# STM32H7B3x register map
File version: 2.2
CPU: CM7 r0p1, little endian, MPU, FPU, 4 interrupt priority bits
Registers are 32-bit, read-write, reset 0x0 unless marked. A register's access mark holds for its fields unless they carry their own. Offsets are from the block's base; [hi:lo] are bit positions; {n}, {i} and the like mark numbered series; 'fields as' and 'values as' point back to an identical list.

## TIM12 — General purpose timers
Base 0x40001800
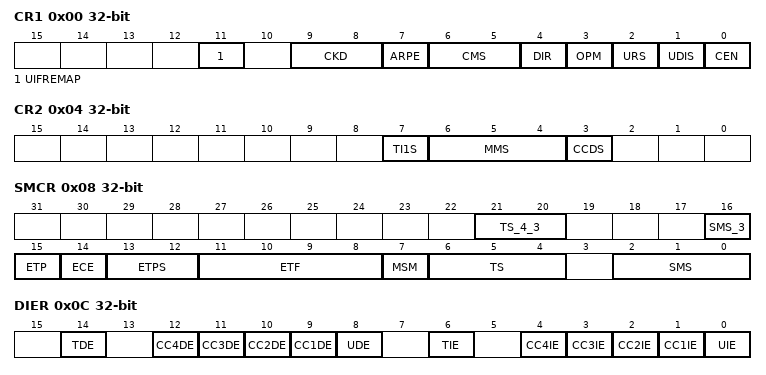
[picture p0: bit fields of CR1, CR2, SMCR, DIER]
0x00 CR1 — control register 1
  [11] UIFREMAP — UIF status bit remapping
  [9:8] CKD — Clock division
    0=Div1 (t_DTS = t_CK_INT); 1=Div2 (t_DTS = 2 × t_CK_INT); 2=Div4 (t_DTS = 4 × t_CK_INT)
  [7] ARPE — Auto-reload preload enable
    0=Disabled (TIMx_APRR register is not buffered); 1=Enabled (TIMx_APRR register is buffered)
  [6:5] CMS — Center-aligned mode selection
  [4] DIR — Direction
  [3] OPM — One-pulse mode
    0=Disabled (Counter is not stopped at update event); 1=Enabled (Counter stops counting at the next update event (clearing the CEN bit))
  [2] URS — Update request source
    0=AnyEvent (Any of counter overflow/underflow, setting UG, or update through slave mode, generates an update interrupt or DMA request); 1=CounterOnly (Only counter overflow/underflow generates an update interrupt or DMA request)
  [1] UDIS — Update disable
    0=Enabled (Update event enabled); 1=Disabled (Update event disabled)
  [0] CEN — Counter enable
    0=Disabled (Counter disabled); 1=Enabled (Counter enabled)
0x04 CR2 — control register 2
  [7] TI1S — TI1 selection
  [6:4] MMS — Master mode selection
  [3] CCDS — Capture/compare DMA selection
0x08 SMCR — slave mode control register
  [21:20] TS_4_3 — Trigger selection
  [16] SMS_3 — Slave mode selection - bit 3
  [15] ETP — External trigger polarity
  [14] ECE — External clock enable
  [13:12] ETPS — External trigger prescaler
  [11:8] ETF — External trigger filter
  [7] MSM — Master/Slave mode
  [6:4] TS — Trigger selection
  [2:0] SMS — Slave mode selection
0x0C DIER — DMA/Interrupt enable register
  [14] TDE — Trigger DMA request enable
  [n+8] CC{n}DE (n=1..4) — Capture/Compare {n} DMA request enable
  [8] UDE — Update DMA request enable
  [6] TIE — Trigger interrupt enable
  [n] CC{n}IE (n=1..4) — Capture/Compare {n} interrupt enable
  [0] UIE — Update interrupt enable
    0=Disabled (Update interrupt disabled); 1=Enabled (Update interrupt enabled)
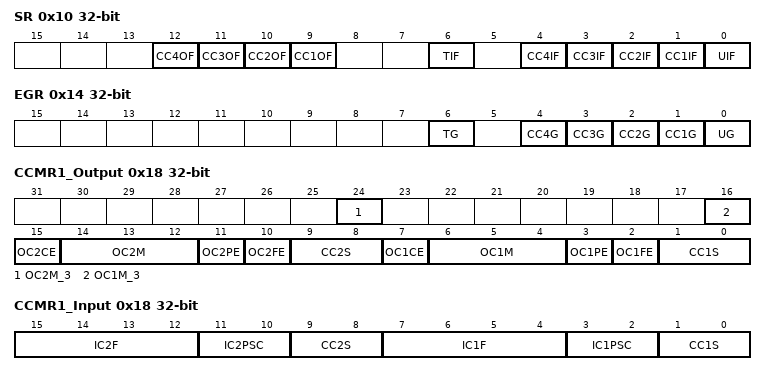
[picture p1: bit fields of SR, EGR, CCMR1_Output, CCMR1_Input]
0x10 SR — status register
  [12] CC4OF — Capture/Compare 4 overcapture flag
  [11] CC3OF — Capture/Compare 3 overcapture flag
  [10] CC2OF — Capture/compare 2 overcapture flag
  [9] CC1OF — Capture/Compare 1 overcapture flag
  [6] TIF — Trigger interrupt flag
  [4] CC4IF — Capture/Compare 4 interrupt flag
  [3] CC3IF — Capture/Compare 3 interrupt flag
  [2] CC2IF — Capture/Compare 2 interrupt flag
  [1] CC1IF — Capture/compare 1 interrupt flag
  [0] UIF write-0-clears — Update interrupt flag
    on read: 0=NoUpdateOccurred; 1=UpdatePending (Update interrupt pending) | on write: 0=Clear flag
0x14 EGR wo — event generation register
  [6] TG — Trigger generation
  [n] CC{n}G (n=1..4) — Capture/compare {n} generation
  [0] UG — Update generation
    on write: 1=Update (Re-initializes the timer counter and generates an update of the registers.)
0x18 CCMR1_Output — capture/compare mode register 1 (output mode)
  [24] OC2M_3 — Output Compare 2 mode - bit 3
    0=Normal output compare mode (modes 0-7); 1=Extended output compare mode (modes 7-15)
  [16] OC1M_3 — Output Compare 1 mode - bit 3
    values as OC2M_3
  [15] OC2CE
  [14:12] OC2M
    0=Frozen (The comparison between the output compare register TIMx_CCRy and the counter TIMx_CNT has no effect on the outputs / OpmMode1: Retriggerable OPM mode 1 - In up-counting mode, the channel is active until a trigger event is detected (on TRGI signal). In down-counting mode, the channel is inactive); 1=ActiveOnMatch (Set channel to active level on match. OCyREF signal is forced high when the counter matches the capture/compare register / OpmMode2: Inversely to OpmMode1); 2=InactiveOnMatch (Set channel to inactive level on match. OCyREF signal is forced low when the counter matches the capture/compare register / Reserved); 3=Toggle (OCyREF toggles when TIMx_CNT=TIMx_CCRy / Reserved); 4=ForceInactive (OCyREF is forced low / CombinedPwmMode1: OCyREF has the same behavior as in PWM mode 1. OCyREFC is the logical OR between OC1REF and OC2REF); 5=ForceActive (OCyREF is forced high / CombinedPwmMode2: OCyREF has the same behavior as in PWM mode 2. OCyREFC is the logical AND between OC1REF and OC2REF); 6=PwmMode1 (In upcounting, channel is active as long as TIMx_CNT<TIMx_CCRy else inactive. In downcounting, channel is inactive as long as TIMx_CNT>TIMx_CCRy else active / Reserved); 7=PwmMode2 (Inversely to PwmMode1 / Reserved)
  [11] OC2PE
    0=Disabled (Preload register on CCR2 disabled. New values written to CCR2 are taken into account immediately); 1=Enabled (Preload register on CCR2 enabled. Preload value is loaded into active register on each update event)
  [10] OC2FE
  [9:8] CC2S
    0=Output (CC2 channel is configured as output)
  [7] OC1CE
  [6:4] OC1M
    values as OC2M
  [3] OC1PE
    0=Disabled (Preload register on CCR1 disabled. New values written to CCR1 are taken into account immediately); 1=Enabled (Preload register on CCR1 enabled. Preload value is loaded into active register on each update event)
  [2] OC1FE
  [1:0] CC1S
    0=Output (CC1 channel is configured as output)
0x18 CCMR1_Input (alternate view of CCMR1_Output) — capture/compare mode register 1 (input mode)
  [15:12] IC2F — Input capture 2 filter
  [11:10] IC2PSC — Input capture 2 prescaler
  [9:8] CC2S — Capture/Compare 2 selection
    1=TI2 (CC2 channel is configured as input, IC2 is mapped on TI2); 2=TI1 (CC2 channel is configured as input, IC2 is mapped on TI1); 3=TRC (CC2 channel is configured as input, IC2 is mapped on TRC)
  [7:4] IC1F — Input capture 1 filter
    0=No filter, sampling is done at fDTS; 1=FCK_INT_N2 (fSAMPLING=fCK_INT, N=2); 2=FCK_INT_N4 (fSAMPLING=fCK_INT, N=4); 3=FCK_INT_N8 (fSAMPLING=fCK_INT, N=8); 4=FDTS_Div2_N6 (fSAMPLING=fDTS/2, N=6); 5=FDTS_Div2_N8 (fSAMPLING=fDTS/2, N=8); 6=FDTS_Div4_N6 (fSAMPLING=fDTS/4, N=6); 7=FDTS_Div4_N8 (fSAMPLING=fDTS/4, N=8); 8=FDTS_Div8_N6 (fSAMPLING=fDTS/8, N=6); 9=FDTS_Div8_N8 (fSAMPLING=fDTS/8, N=8); 10=FDTS_Div16_N5 (fSAMPLING=fDTS/16, N=5); 11=FDTS_Div16_N6 (fSAMPLING=fDTS/16, N=6); 12=FDTS_Div16_N8 (fSAMPLING=fDTS/16, N=8); 13=FDTS_Div32_N5 (fSAMPLING=fDTS/32, N=5); 14=FDTS_Div32_N6 (fSAMPLING=fDTS/32, N=6); 15=FDTS_Div32_N8 (fSAMPLING=fDTS/32, N=8)
  [3:2] IC1PSC — Input capture 1 prescaler
  [1:0] CC1S — Capture/Compare 1 selection
    1=TI1 (CC1 channel is configured as input, IC1 is mapped on TI1); 2=TI2 (CC1 channel is configured as input, IC1 is mapped on TI2); 3=TRC (CC1 channel is configured as input, IC1 is mapped on TRC)
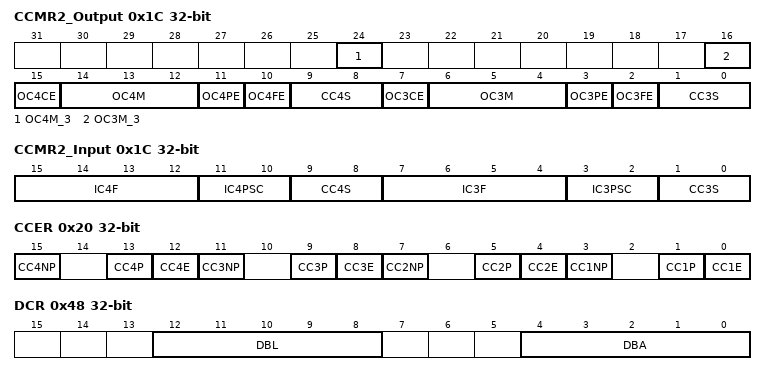
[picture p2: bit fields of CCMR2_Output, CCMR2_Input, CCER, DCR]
0x1C CCMR2_Output — capture/compare mode register 2 (output mode)
  [24] OC4M_3 — Output Compare 2 mode - bit 3
    values as CCMR1_Output.OC2M_3
  [16] OC3M_3 — Output Compare 1 mode - bit 3
    values as CCMR1_Output.OC2M_3
  [15] OC4CE
  [14:12] OC4M
    values as CCMR1_Output.OC2M
  [11] OC4PE
  [10] OC4FE
  [9:8] CC4S
  [7] OC3CE
  [6:4] OC3M
    values as CCMR1_Output.OC2M
  [3] OC3PE
  [2] OC3FE
  [1:0] CC3S
0x1C CCMR2_Input (alternate view of CCMR2_Output) — capture/compare mode register 2 (input mode)
  [15:12] IC4F — Input capture 4 filter
  [11:10] IC4PSC — Input capture 4 prescaler
  [9:8] CC4S — Capture/Compare 4 selection
  [7:4] IC3F — Input capture 3 filter
  [3:2] IC3PSC — Input capture 3 prescaler
  [1:0] CC3S — Capture/compare 3 selection
0x20 CCER — capture/compare enable register
  [4n-1] CC{n}NP (n=1..4) — Capture/Compare {n} output Polarity
  [13] CC4P — Capture/Compare 3 output Polarity
  [4n-4] CC{n}E (n=1..4) — Capture/Compare {n} output enable
  [9] CC3P — Capture/Compare 3 output Polarity
  [5] CC2P — Capture/Compare 2 output Polarity
  [1] CC1P — Capture/Compare 1 output Polarity
0x24 CNT — counter
  [15:0] CNT — Counter value
0x28 PSC — prescaler
  [15:0] PSC — Prescaler value
0x2C ARR — auto-reload register
  [15:0] ARR — Auto-reload value
{0x30+4i} CCR{i} (i=1..2) — capture/compare register
  [15:0] CCR — Capture/Compare 1 value
0x48 DCR — DMA control register
  [12:8] DBL — DMA burst length
  [4:0] DBA — DMA base address
0x4C DMAR — DMA address for full transfer
  [15:0] DMAB — DMA register for burst accesses
0x60 AF1 — TIM alternate function option register 1
  [17:14] ETRSEL — ETR source selection
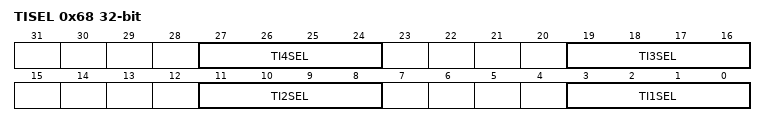
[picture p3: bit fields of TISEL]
0x68 TISEL — TIM timer input selection register
  [8n-5:8n-8] TI{n}SEL (n=1..4) — TI{n}[0] to TI{n}[15] input selection
